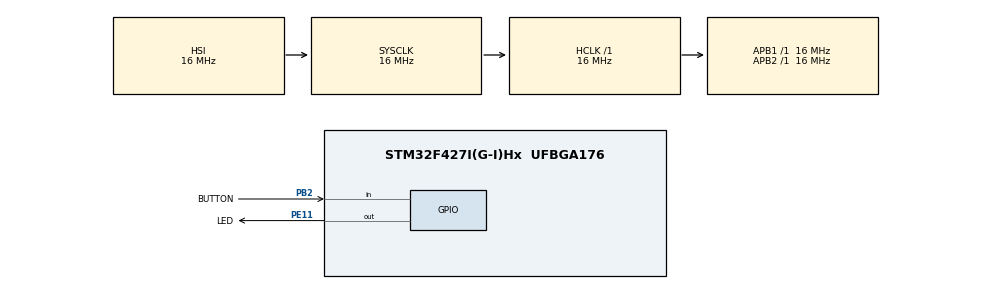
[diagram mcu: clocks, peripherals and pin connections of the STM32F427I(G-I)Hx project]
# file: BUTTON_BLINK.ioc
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Mcu.Family=STM32F4
Mcu.Name=STM32F427I(G-I)Hx
Mcu.Package=UFBGA176
NVIC.PriorityGroup=NVIC_PRIORITYGROUP_4
PB2/BOOT1.GPIO_Label=BUTTON
PB2/BOOT1.Signal=GPIO_Input
PE11.GPIO_Label=LED
PE11.Signal=GPIO_Output
ProjectManager.HeapSize=0x200
ProjectManager.StackSize=0x400
ProjectManager.TargetToolchain=MDK-ARM V5
RCC.AHBFreq_Value=16000000
RCC.APB1Freq_Value=16000000
RCC.APB2Freq_Value=16000000
RCC.CortexFreq_Value=16000000
RCC.HSE_VALUE=25000000
RCC.HSI_VALUE=16000000
RCC.LSE_VALUE=32768
RCC.SYSCLKFreq_VALUE=16000000
RCC.VCOOutputFreq_Value=192000000
board=custom

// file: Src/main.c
// AUTHOR: Jin Wei
// AFFILIATION: Fudan Univ.
// BOARD: DJI Development Board Type A
// CONTROLLER: STM32F427IIH6
// FUNCTION: LED turns on when pressing the button and maintains for a while after releasing the button.
// DESCRIPTION:
//     LED: E11, red; initially 1; 0 - on, 1 - off
//     button: B2, white; 0 - release, 1 - press
//     LED on duration: 0.5 sec

/* USER CODE BEGIN Header */
/**
  ******************************************************************************
  * @file           : main.c
  * @brief          : Main program body
  ******************************************************************************
  * @attention
  *
  * <h2><center>&copy; Copyright (c) 2021 STMicroelectronics.
  * All rights reserved.</center></h2>
  *
  * This software component is licensed by ST under BSD 3-Clause license,
  * the "License"; You may not use this file except in compliance with the
  * License. You may obtain a copy of the License at:
  *                        opensource.org/licenses/BSD-3-Clause
  *
  ******************************************************************************
  */
/* USER CODE END Header */
#include "main.h"
#include "gpio.h"

void SystemClock_Config(void);

int main(void)
{

  /* MCU Configuration--------------------------------------------------------*/

  /* Reset of all peripherals, Initializes the Flash interface and the Systick. */
  HAL_Init();

  /* Configure the system clock */
  SystemClock_Config();

  /* Initialize all configured peripherals */
  MX_GPIO_Init();
  /* USER CODE BEGIN 2 */
	HAL_GPIO_WritePin(LED_GPIO_Port, LED_Pin, GPIO_PIN_SET); // set LED to be extinguished at first
  /* USER CODE END 2 */

  /* Infinite loop */
  /* USER CODE BEGIN WHILE */
  while (1)
  {
		if(HAL_GPIO_ReadPin(BUTTON_GPIO_Port, BUTTON_Pin)){ // if button is pressed
			HAL_GPIO_WritePin(LED_GPIO_Port, LED_Pin, GPIO_PIN_RESET); // light on for 0.5 sec
			HAL_Delay(500);
			HAL_GPIO_WritePin(LED_GPIO_Port, LED_Pin, GPIO_PIN_SET); // light off
		}
    /* USER CODE END WHILE */

  }
}

void SystemClock_Config(void)
{
  RCC_OscInitTypeDef RCC_OscInitStruct = {0};
  RCC_ClkInitTypeDef RCC_ClkInitStruct = {0};

  /** Configure the main internal regulator output voltage
  */
  __HAL_RCC_PWR_CLK_ENABLE();
  __HAL_PWR_VOLTAGESCALING_CONFIG(PWR_REGULATOR_VOLTAGE_SCALE3);
  /** Initializes the RCC Oscillators according to the specified parameters
  * in the RCC_OscInitTypeDef structure.
  */
  RCC_OscInitStruct.OscillatorType = RCC_OSCILLATORTYPE_HSI;
  RCC_OscInitStruct.HSIState = RCC_HSI_ON;
  RCC_OscInitStruct.HSICalibrationValue = RCC_HSICALIBRATION_DEFAULT;
  RCC_OscInitStruct.PLL.PLLState = RCC_PLL_NONE;
  if (HAL_RCC_OscConfig(&RCC_OscInitStruct) != HAL_OK)
  {
    Error_Handler();
  }
  /** Initializes the CPU, AHB and APB buses clocks
  */
  RCC_ClkInitStruct.ClockType = RCC_CLOCKTYPE_HCLK|RCC_CLOCKTYPE_SYSCLK
                              |RCC_CLOCKTYPE_PCLK1|RCC_CLOCKTYPE_PCLK2;
  RCC_ClkInitStruct.SYSCLKSource = RCC_SYSCLKSOURCE_HSI;
  RCC_ClkInitStruct.AHBCLKDivider = RCC_SYSCLK_DIV1;
  RCC_ClkInitStruct.APB1CLKDivider = RCC_HCLK_DIV1;
  RCC_ClkInitStruct.APB2CLKDivider = RCC_HCLK_DIV1;

  if (HAL_RCC_ClockConfig(&RCC_ClkInitStruct, FLASH_LATENCY_0) != HAL_OK)
  {
    Error_Handler();
  }
}

void Error_Handler(void)
{
  __disable_irq();
  while (1)
  {
  }
}

/************************ (C) COPYRIGHT STMicroelectronics *****END OF FILE****/
